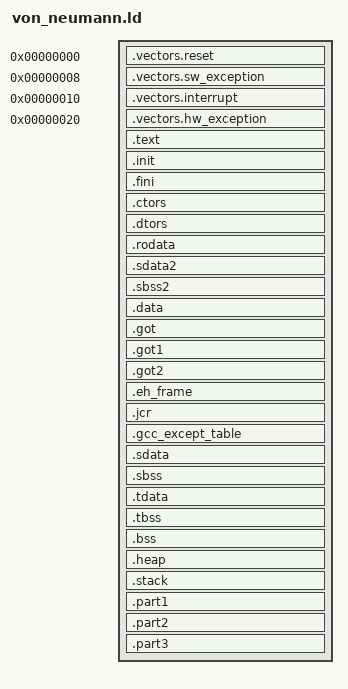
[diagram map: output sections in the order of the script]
/*******************************************************************/
/*                                                                 */
/* This file is automatically generated by linker script generator.*/
/*                                                                 */
/* Version:                                 */
/*                                                                 */
/* Copyright (c) 2010-2016 Xilinx, Inc.  All rights reserved.      */
/*                                                                 */
/* Description : MicroBlaze Linker Script                          */
/*                                                                 */
/*******************************************************************/

_STACK_SIZE = DEFINED(_STACK_SIZE) ? _STACK_SIZE : 0x0800;
_HEAP_SIZE = DEFINED(_HEAP_SIZE) ? _HEAP_SIZE : 0x100;


/* Specify the default entry point to the program */

ENTRY(_start)

/* Define the sections, and where they are mapped in memory */

SECTIONS
{
.vectors.reset 0x0 : {
   KEEP (*(.vectors.reset))
} 

.vectors.sw_exception 0x8 : {
   KEEP (*(.vectors.sw_exception))
} 

.vectors.interrupt 0x10 : {
   KEEP (*(.vectors.interrupt))
} 

.vectors.hw_exception 0x20 : {
   KEEP (*(.vectors.hw_exception))
} 

.text : {
   *(.text)
   *(.text.*)
   *(.gnu.linkonce.t.*)
} > mem

.init : {
   KEEP (*(.init))
} > mem

.fini : {
   KEEP (*(.fini))
} > mem

.ctors : {
   __CTOR_LIST__ = .;
   ___CTORS_LIST___ = .;
   KEEP (*crtbegin.o(.ctors))
   KEEP (*(EXCLUDE_FILE(*crtend.o) .ctors))
   KEEP (*(SORT(.ctors.*)))
   KEEP (*(.ctors))
   __CTOR_END__ = .;
   ___CTORS_END___ = .;
} > mem

.dtors : {
   __DTOR_LIST__ = .;
   ___DTORS_LIST___ = .;
   KEEP (*crtbegin.o(.dtors))
   KEEP (*(EXCLUDE_FILE(*crtend.o) .dtors))
   KEEP (*(SORT(.dtors.*)))
   KEEP (*(.dtors))
   PROVIDE(__DTOR_END__ = .);
   PROVIDE(___DTORS_END___ = .);
} > mem

.rodata : {
   __rodata_start = .;
   *(.rodata)
   *(.rodata.*)
   *(.gnu.linkonce.r.*)
   __rodata_end = .;
} > mem

.sdata2 : {
   . = ALIGN(8);
   __sdata2_start = .;
   *(.sdata2)
   *(.sdata2.*)
   *(.gnu.linkonce.s2.*)
   . = ALIGN(8);
   __sdata2_end = .;
} > mem

.sbss2 : {
   __sbss2_start = .;
   *(.sbss2)
   *(.sbss2.*)
   *(.gnu.linkonce.sb2.*)
   __sbss2_end = .;
} > mem

.data : {
   . = ALIGN(4);
   __data_start = .;
   *(.data)
   *(.data.*)
   *(.gnu.linkonce.d.*)
   __data_end = .;
} > mem

.got : {
   *(.got)
} > mem

.got1 : {
   *(.got1)
} > mem

.got2 : {
   *(.got2)
} > mem

.eh_frame : {
   *(.eh_frame)
} > mem

.jcr : {
   *(.jcr)
} > mem

.gcc_except_table : {
   *(.gcc_except_table)
} > mem

.sdata : {
   . = ALIGN(8);
   __sdata_start = .;
   *(.sdata)
   *(.sdata.*)
   *(.gnu.linkonce.s.*)
   __sdata_end = .;
} > mem

.sbss (NOLOAD) : {
   . = ALIGN(4);
   __sbss_start = .;
   *(.sbss)
   *(.sbss.*)
   *(.gnu.linkonce.sb.*)
   . = ALIGN(8);
   __sbss_end = .;
} > mem

.tdata : {
   __tdata_start = .;
   *(.tdata)
   *(.tdata.*)
   *(.gnu.linkonce.td.*)
   __tdata_end = .;
} > mem

.tbss : {
   __tbss_start = .;
   *(.tbss)
   *(.tbss.*)
   *(.gnu.linkonce.tb.*)
   __tbss_end = .;
} > mem

.bss (NOLOAD) : {
   . = ALIGN(4);
   __bss_start = .;
   *(.bss)
   *(.bss.*)
   *(.gnu.linkonce.b.*)
   *(COMMON)
   . = ALIGN(4);
   __bss_end = .;
} > mem

_SDA_BASE_ = __sdata_start + ((__sbss_end - __sdata_start) / 2 );

_SDA2_BASE_ = __sdata2_start + ((__sbss2_end - __sdata2_start) / 2 );

/* Generate Stack and Heap definitions */

.heap (NOLOAD) : {
   . = ALIGN(8);
   _heap = .;
   _heap_start = .;
   . += _HEAP_SIZE;
   _heap_end = .;
} > mem

.stack (NOLOAD) : {
   _stack_end = .;
   . += _STACK_SIZE;
   . = ALIGN(8);
   _stack = .;
   __stack = _stack;
} > mem

/*.part2 : { . = ALIGN(4); . += 0x08000; } > mem2*/
/*.part3 : { . = ALIGN(4); . +=4; } > mem3*/
.part1 : {
    . = ALIGN(4);
    . += 0x08000;
} > mem2
.part2 : {
    . = ALIGN(4);
    . += 0x08000;
} > mem3
.part3 : {
    . = ALIGN(4);
    . += 0x08000;
} > mem4
_end = .;
/*
.partition_2_text : { . = ALIGN(4); . += 4;} > mem2
.partition_3_text : { . = ALIGN(4); . += 4;} > mem3
.partition_4_text : { . = ALIGN(4); . += 4;} > mem4
.partition_2_init : { . = ALIGN(4); . += 4;} > mem2
.partition_2_fini : { . = ALIGN(4); . += 4;} > mem2
.partition_2_ctors : { . = ALIGN(4); . += 4;} > mem2
.partition_2_dtors : { . = ALIGN(4); . += 4;} > mem2
.partition_2_rodata : { . = ALIGN(4); . += 4;} > mem2
.partition_2_sdata2 : { . = ALIGN(4); . += 4;} > mem2
.partition_2_sbss2 : { . = ALIGN(4); . += 4;} > mem2
.partition_2_data : { . = ALIGN(4); . += 4;} > mem2
.partition_2_got : { . = ALIGN(4); . += 4;} > mem2
.partition_2_got1 : { . = ALIGN(4); . += 4;} > mem2
.partition_2_got2 : { . = ALIGN(4); . += 4;} > mem2
.partition_2_eh_frame : { . = ALIGN(4); . += 4;} > mem2
.partition_2_jcr : { . = ALIGN(4); . += 4;} > mem2
.partition_2_gcc_except_table : { . = ALIGN(4); . += 4;} > mem2
.partition_2_sdata : { . = ALIGN(4); . += 4;} > mem2
.partition_2_sbss (NOLOAD) : { . = ALIGN(4); . += 4;} > mem2
.partition_2_tdata : { . = ALIGN(4); . += 4;} > mem2
.partition_2_tbss : { . = ALIGN(4); . += 4;} > mem2
.partition_2_bss (NOLOAD) : { . = ALIGN(4); . += 4;} > mem2
*/
}
